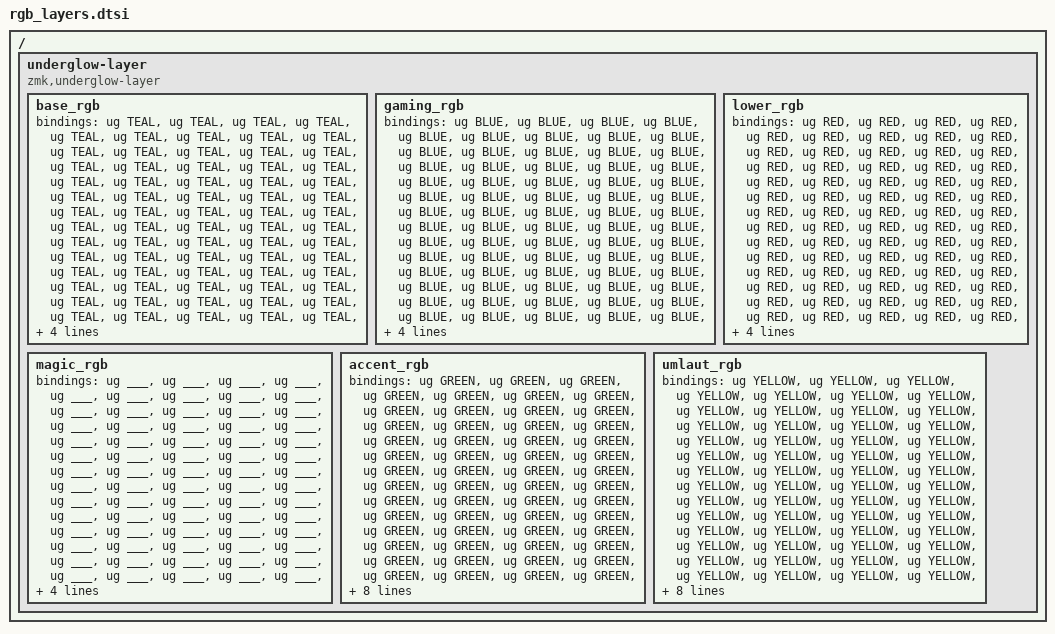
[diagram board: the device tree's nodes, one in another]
/*
 * RGB Underglow Per-Layer Configuration
 * Based on darknao/zmk fork (rgb-layer-25.08)
 *
 * Colors:
 *   Base    (0) = TEAL
 *   Gaming  (1) = BLUE
 *   Lower   (2) = RED
 *   Magic   (3) = off
 *   Accent  (4) = GREEN
 *   Umlaut  (5) = YELLOW
 */

/ {
    underglow-layer {
        compatible = "zmk,underglow-layer";

        base_rgb {
            bindings = <
    &ug TEAL &ug TEAL &ug TEAL &ug TEAL &ug TEAL                                                                  &ug TEAL &ug TEAL &ug TEAL &ug TEAL &ug TEAL
    &ug TEAL &ug TEAL &ug TEAL &ug TEAL &ug TEAL &ug TEAL                                                  &ug TEAL &ug TEAL &ug TEAL &ug TEAL &ug TEAL &ug TEAL
    &ug TEAL &ug TEAL &ug TEAL &ug TEAL &ug TEAL &ug TEAL                                                  &ug TEAL &ug TEAL &ug TEAL &ug TEAL &ug TEAL &ug TEAL
    &ug TEAL &ug TEAL &ug TEAL &ug TEAL &ug TEAL &ug TEAL                                                  &ug TEAL &ug TEAL &ug TEAL &ug TEAL &ug TEAL &ug TEAL
    &ug TEAL &ug TEAL &ug TEAL &ug TEAL &ug TEAL &ug TEAL &ug TEAL &ug TEAL &ug TEAL  &ug TEAL &ug TEAL &ug TEAL &ug TEAL &ug TEAL &ug TEAL &ug TEAL &ug TEAL &ug TEAL
    &ug TEAL &ug TEAL &ug TEAL &ug TEAL &ug TEAL          &ug TEAL &ug TEAL &ug TEAL  &ug TEAL &ug TEAL &ug TEAL          &ug TEAL &ug TEAL &ug TEAL &ug TEAL &ug TEAL
                >;
            layer-id = <0>;
        };

        gaming_rgb {
            bindings = <
    &ug BLUE &ug BLUE &ug BLUE &ug BLUE &ug BLUE                                                                  &ug BLUE &ug BLUE &ug BLUE &ug BLUE &ug BLUE
    &ug BLUE &ug BLUE &ug BLUE &ug BLUE &ug BLUE &ug BLUE                                                  &ug BLUE &ug BLUE &ug BLUE &ug BLUE &ug BLUE &ug BLUE
    &ug BLUE &ug BLUE &ug BLUE &ug BLUE &ug BLUE &ug BLUE                                                  &ug BLUE &ug BLUE &ug BLUE &ug BLUE &ug BLUE &ug BLUE
    &ug BLUE &ug BLUE &ug BLUE &ug BLUE &ug BLUE &ug BLUE                                                  &ug BLUE &ug BLUE &ug BLUE &ug BLUE &ug BLUE &ug BLUE
    &ug BLUE &ug BLUE &ug BLUE &ug BLUE &ug BLUE &ug BLUE &ug BLUE &ug BLUE &ug BLUE  &ug BLUE &ug BLUE &ug BLUE &ug BLUE &ug BLUE &ug BLUE &ug BLUE &ug BLUE &ug BLUE
    &ug BLUE &ug BLUE &ug BLUE &ug BLUE &ug BLUE          &ug BLUE &ug BLUE &ug BLUE  &ug BLUE &ug BLUE &ug BLUE          &ug BLUE &ug BLUE &ug BLUE &ug BLUE &ug BLUE
                >;
            layer-id = <1>;
        };

        lower_rgb {
            bindings = <
    &ug RED &ug RED &ug RED &ug RED &ug RED                                                                  &ug RED &ug RED &ug RED &ug RED &ug RED
    &ug RED &ug RED &ug RED &ug RED &ug RED &ug RED                                                  &ug RED &ug RED &ug RED &ug RED &ug RED &ug RED
    &ug RED &ug RED &ug RED &ug RED &ug RED &ug RED                                                  &ug RED &ug RED &ug RED &ug RED &ug RED &ug RED
    &ug RED &ug RED &ug RED &ug RED &ug RED &ug RED                                                  &ug RED &ug RED &ug RED &ug RED &ug RED &ug RED
    &ug RED &ug RED &ug RED &ug RED &ug RED &ug RED &ug RED &ug RED &ug RED  &ug RED &ug RED &ug RED &ug RED &ug RED &ug RED &ug RED &ug RED &ug RED
    &ug RED &ug RED &ug RED &ug RED &ug RED          &ug RED &ug RED &ug RED  &ug RED &ug RED &ug RED          &ug RED &ug RED &ug RED &ug RED &ug RED
                >;
            layer-id = <2>;
        };

        magic_rgb {
            bindings = <
    &ug ___ &ug ___ &ug ___ &ug ___ &ug ___                                                                  &ug ___ &ug ___ &ug ___ &ug ___ &ug ___
    &ug ___ &ug ___ &ug ___ &ug ___ &ug ___ &ug ___                                                  &ug ___ &ug ___ &ug ___ &ug ___ &ug ___ &ug ___
    &ug ___ &ug ___ &ug ___ &ug ___ &ug ___ &ug ___                                                  &ug ___ &ug ___ &ug ___ &ug ___ &ug ___ &ug ___
    &ug ___ &ug ___ &ug ___ &ug ___ &ug ___ &ug ___                                                  &ug ___ &ug ___ &ug ___ &ug ___ &ug ___ &ug ___
    &ug ___ &ug ___ &ug ___ &ug ___ &ug ___ &ug ___ &ug ___ &ug ___ &ug ___  &ug ___ &ug ___ &ug ___ &ug ___ &ug ___ &ug ___ &ug ___ &ug ___ &ug ___
    &ug ___ &ug ___ &ug ___ &ug ___ &ug ___         &ug ___ &ug ___ &ug ___  &ug ___ &ug ___ &ug ___         &ug ___ &ug ___ &ug ___ &ug ___ &ug ___
                >;
            layer-id = <3>;
        };

        accent_rgb {
            bindings = <
    &ug GREEN &ug GREEN &ug GREEN &ug GREEN &ug GREEN                                                                  &ug GREEN &ug GREEN &ug GREEN &ug GREEN &ug GREEN
    &ug GREEN &ug GREEN &ug GREEN &ug GREEN &ug GREEN &ug GREEN                                                  &ug GREEN &ug GREEN &ug GREEN &ug GREEN &ug GREEN &ug GREEN
    &ug GREEN &ug GREEN &ug GREEN &ug GREEN &ug GREEN &ug GREEN                                                  &ug GREEN &ug GREEN &ug GREEN &ug GREEN &ug GREEN &ug GREEN
    &ug GREEN &ug GREEN &ug GREEN &ug GREEN &ug GREEN &ug GREEN                                                  &ug GREEN &ug GREEN &ug GREEN &ug GREEN &ug GREEN &ug GREEN
    &ug GREEN &ug GREEN &ug GREEN &ug GREEN &ug GREEN &ug GREEN &ug GREEN &ug GREEN &ug GREEN  &ug GREEN &ug GREEN &ug GREEN &ug GREEN &ug GREEN &ug GREEN &ug GREEN &ug GREEN &ug GREEN
    &ug GREEN &ug GREEN &ug GREEN &ug GREEN &ug GREEN          &ug GREEN &ug GREEN &ug GREEN  &ug GREEN &ug GREEN &ug GREEN          &ug GREEN &ug GREEN &ug GREEN &ug GREEN &ug GREEN
                >;
            layer-id = <4>;
        };

        umlaut_rgb {
            bindings = <
    &ug YELLOW &ug YELLOW &ug YELLOW &ug YELLOW &ug YELLOW                                                                  &ug YELLOW &ug YELLOW &ug YELLOW &ug YELLOW &ug YELLOW
    &ug YELLOW &ug YELLOW &ug YELLOW &ug YELLOW &ug YELLOW &ug YELLOW                                                  &ug YELLOW &ug YELLOW &ug YELLOW &ug YELLOW &ug YELLOW &ug YELLOW
    &ug YELLOW &ug YELLOW &ug YELLOW &ug YELLOW &ug YELLOW &ug YELLOW                                                  &ug YELLOW &ug YELLOW &ug YELLOW &ug YELLOW &ug YELLOW &ug YELLOW
    &ug YELLOW &ug YELLOW &ug YELLOW &ug YELLOW &ug YELLOW &ug YELLOW                                                  &ug YELLOW &ug YELLOW &ug YELLOW &ug YELLOW &ug YELLOW &ug YELLOW
    &ug YELLOW &ug YELLOW &ug YELLOW &ug YELLOW &ug YELLOW &ug YELLOW &ug YELLOW &ug YELLOW &ug YELLOW  &ug YELLOW &ug YELLOW &ug YELLOW &ug YELLOW &ug YELLOW &ug YELLOW &ug YELLOW &ug YELLOW &ug YELLOW
    &ug YELLOW &ug YELLOW &ug YELLOW &ug YELLOW &ug YELLOW          &ug YELLOW &ug YELLOW &ug YELLOW  &ug YELLOW &ug YELLOW &ug YELLOW          &ug YELLOW &ug YELLOW &ug YELLOW &ug YELLOW &ug YELLOW
                >;
            layer-id = <5>;
        };
    };
};
